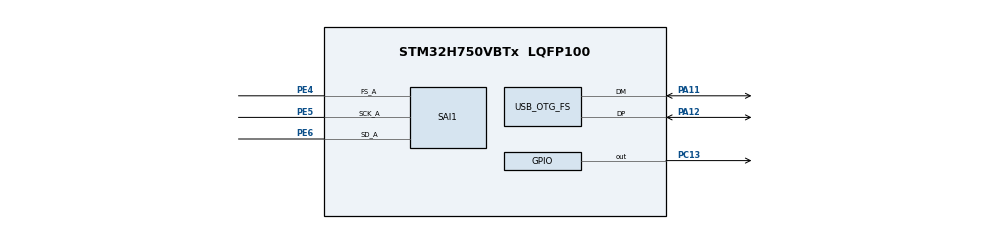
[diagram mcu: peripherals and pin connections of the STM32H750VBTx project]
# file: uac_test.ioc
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CORTEX_M7.default_mode_Activation=1
Dma.Request0=SAI1_A
Dma.SAI1_A.0.Direction=DMA_MEMORY_TO_PERIPH
Dma.SAI1_A.0.EventEnable=DISABLE
Dma.SAI1_A.0.FIFOMode=DMA_FIFOMODE_DISABLE
Dma.SAI1_A.0.Instance=DMA1_Stream0
Dma.SAI1_A.0.MemDataAlignment=DMA_MDATAALIGN_WORD
Dma.SAI1_A.0.MemInc=DMA_MINC_ENABLE
Dma.SAI1_A.0.Mode=DMA_CIRCULAR
Dma.SAI1_A.0.PeriphDataAlignment=DMA_PDATAALIGN_WORD
Dma.SAI1_A.0.PeriphInc=DMA_PINC_DISABLE
Dma.SAI1_A.0.Polarity=HAL_DMAMUX_REQ_GEN_RISING
Dma.SAI1_A.0.Priority=DMA_PRIORITY_LOW
Dma.SAI1_A.0.RequestNumber=1
Dma.SAI1_A.0.SignalID=NONE
Dma.SAI1_A.0.SyncEnable=DISABLE
Dma.SAI1_A.0.SyncPolarity=HAL_DMAMUX_SYNC_NO_EVENT
Dma.SAI1_A.0.SyncRequestNumber=1
Dma.SAI1_A.0.SyncSignalID=NONE
Mcu.Family=STM32H7
Mcu.Name=STM32H750VBTx
Mcu.Package=LQFP100
NVIC.DMA1_Stream0_IRQn=true\:0\:0\:false\:false\:true\:false\:true\:true
NVIC.OTG_FS_IRQn=true\:0\:0\:false\:false\:true\:false\:true\:true
NVIC.PriorityGroup=NVIC_PRIORITYGROUP_4
PA11.Mode=Device_Only
PA11.Signal=USB_OTG_FS_DM
PA12.Mode=Device_Only
PA12.Signal=USB_OTG_FS_DP
PA13\ (JTMS/SWDIO).Mode=Serial_Wire
PA13\ (JTMS/SWDIO).Signal=DEBUG_JTMS-SWDIO
PA14\ (JTCK/SWCLK).Mode=Serial_Wire
PA14\ (JTCK/SWCLK).Signal=DEBUG_JTCK-SWCLK
PC13.Signal=GPIO_Output
PE4.Mode=SAI_A_Master
PE4.Signal=SAI1_FS_A
PE5.Mode=SAI_A_Master
PE5.Signal=SAI1_SCK_A
PE6.Mode=SAI_A_Master
PE6.Signal=SAI1_SD_A
PH0-OSC_IN\ (PH0).Mode=HSE-External-Oscillator
PH0-OSC_IN\ (PH0).Signal=RCC_OSC_IN
PH1-OSC_OUT\ (PH1).Mode=HSE-External-Oscillator
PH1-OSC_OUT\ (PH1).Signal=RCC_OSC_OUT
ProjectManager.HeapSize=0x4000
ProjectManager.StackSize=0x1000
ProjectManager.TargetToolchain=CMake
RCC.ADCFreq_Value=24576004.028320312
RCC.APB1Freq_Value=120000000
RCC.APB2Freq_Value=120000000
RCC.APB3Freq_Value=120000000
RCC.APB4Freq_Value=120000000
RCC.CortexFreq_Value=480000000
RCC.D1PPRE=RCC_APB3_DIV2
RCC.D2PPRE1=RCC_APB1_DIV2
RCC.D2PPRE2=RCC_APB2_DIV2
RCC.D3PPRE=RCC_APB4_DIV2
RCC.DIVM1=1
RCC.DIVM2=2
RCC.DIVN1=240
RCC.DIVN2=393
RCC.DIVP2=32
RCC.DIVQ1=15
RCC.HCLKFreq_Value=240000000
RCC.HPRE=RCC_HCLK_DIV2
RCC.PLL2FRACN=1770
RCC.PLL3FRACN=0
RCC.PLLFRACN=0
RCC.PLLSourceVirtual=RCC_PLLSOURCE_CSI
RCC.SAI1CLockSelection=RCC_SAI1CLKSOURCE_PLL2
RCC.SPI123CLockSelection=RCC_SPI123CLKSOURCE_PLL2
RCC.SYSCLKFreq_VALUE=480000000
RCC.SYSCLKSource=RCC_SYSCLKSOURCE_PLLCLK
RCC.USBCLockSelection=RCC_USBCLKSOURCE_HSI48
RCC.USBFreq_Value=48000000
SAI1.AudioFrequency-SAI_A_Master=SAI_AUDIO_FREQUENCY_48K
SAI1.BasicDataSize-SAI_A_Master=SAI_PROTOCOL_DATASIZE_32BIT
SAI1.ErrorAudioFreq-SAI_A_Master=100.0 %
SAI1.InitProtocol-SAI_A_Master=Enable
SAI1.Instance-SAI_A_Master=SAI$Index_Block_A
SAI1.MClockEnable=SAI_MASTERCLOCK_DISABLE
SAI1.MonoStereoMode-SAI_A_Master=SAI_STEREOMODE
SAI1.NoDivider-SAI_A_Master=SAI_MCK_OVERSAMPLING_DISABLE
SAI1.RealAudioFreq-SAI_A_Master=96.0 KHz
SAI1.VirtualMode-SAI_A_Master=VM_MASTER
SAI1.VirtualProtocol-SAI_A_BASIC=VM_BASIC_PROTOCOL
USB_DEVICE.CLASS_NAME_FS=AUDIO
USB_DEVICE.MANUFACTURER_STRING-AUDIO_FS=STM32_6676
USB_DEVICE.PID_AUDIO_FS=0x5730
USB_DEVICE.PRODUCT_STRING_AUDIO_FS=Audio Class
USB_DEVICE.USBD_AUDIO_FREQ-AUDIO_FS=48000
USB_DEVICE.VirtualMode-AUDIO_FS=Audio
USB_DEVICE.VirtualModeFS=Audio_FS
USB_OTG_FS.VirtualMode=Device_Only
VP_MEMORYMAP_VS_MEMORYMAP.Mode=CurAppReg
VP_SAI1_VP_$IpInstance_SAIA_SAI_BASIC.Mode=SAI_A_BASIC
VP_USB_DEVICE_VS_USB_DEVICE_AUDIO_FS.Mode=AUDIO_FS
board=custom

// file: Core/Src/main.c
/* USER CODE BEGIN Header */
/**
  ******************************************************************************
  * @file           : main.c
  * @brief          : Main program body
  ******************************************************************************
  * @attention
  *
  * Copyright (c) 2026 STMicroelectronics.
  * All rights reserved.
  *
  * This software is licensed under terms that can be found in the LICENSE file
  * in the root directory of this software component.
  * If no LICENSE file comes with this software, it is provided AS-IS.
  *
  ******************************************************************************
  */
/* USER CODE END Header */
#include "main.h"
#include "dma.h"
#include "sai.h"
#include "usb_device.h"
#include "gpio.h"

/* USER CODE BEGIN Includes */
#include "math.h"
/* USER CODE END Includes */

void SystemClock_Config(void);
static void MPU_Config(void);

/* USER CODE BEGIN 0 */
//#define buff_len 192*2
//#define pi 3.14159265358979

//int32_t sine_wave[192];
//int32_t i2s_buff[100];

/* USER CODE END 0 */

int main(void)
{

  /* MPU Configuration--------------------------------------------------------*/
  MPU_Config();

  /* MCU Configuration--------------------------------------------------------*/

  /* Reset of all peripherals, Initializes the Flash interface and the Systick. */
  HAL_Init();

  /* Configure the system clock */
  SystemClock_Config();

  /* Initialize all configured peripherals */
  MX_GPIO_Init();
  MX_DMA_Init();
  MX_USB_DEVICE_Init();
  MX_SAI1_Init();
  /* USER CODE BEGIN 2 */

//		for(uint32_t i=0;i<buff_len/2;i++)
//	{
//		sine_wave[i]=2000000000.0*sin(2.0*pi*i/(buff_len/2));
//	}
//	for(uint32_t i=0;i<buff_len/2;i++)
//	{
//		uint32_t index_r=2*i+1;
//		uint32_t index_l=2*i;
//		if(i<buff_len/4)
//			i2s_buff[index_l]=(i-buff_len/8)*3000000;
//		else
//			i2s_buff[index_l]=(-i+buff_len*3/8)*3000000;
//
//		i2s_buff[index_r]=sine_wave[i];//i2s_buff[index_l]=sine_wave[i];
////		i2s_buff[index_r]=((i2s_buff[index_r]&0x0000ffff)<<16)|((i2s_buff[index_r]&0xffff0000)>>16);
////		i2s_buff[index_l]=((i2s_buff[index_l]&0x0000ffff)<<16)|((i2s_buff[index_l]&0xffff0000)>>16);
//	}
	//HAL_SAI_Transmit_DMA(&hsai_BlockA1,(uint8_t *)i2s_buff,100);
  /* USER CODE END 2 */

  /* Infinite loop */
  /* USER CODE BEGIN WHILE */
  while (1)
  {
		HAL_Delay(500);

    /* USER CODE END WHILE */

  }
}

void SystemClock_Config(void)
{
  RCC_OscInitTypeDef RCC_OscInitStruct = {0};
  RCC_ClkInitTypeDef RCC_ClkInitStruct = {0};

  /** Supply configuration update enable
  */
  HAL_PWREx_ConfigSupply(PWR_LDO_SUPPLY);

  /** Configure the main internal regulator output voltage
  */
  __HAL_PWR_VOLTAGESCALING_CONFIG(PWR_REGULATOR_VOLTAGE_SCALE0);

  while(!__HAL_PWR_GET_FLAG(PWR_FLAG_VOSRDY)) {}

  /** Initializes the RCC Oscillators according to the specified parameters
  * in the RCC_OscInitTypeDef structure.
  */
  RCC_OscInitStruct.OscillatorType = RCC_OSCILLATORTYPE_HSI48|RCC_OSCILLATORTYPE_CSI;
  RCC_OscInitStruct.HSI48State = RCC_HSI48_ON;
  RCC_OscInitStruct.CSIState = RCC_CSI_ON;
  RCC_OscInitStruct.CSICalibrationValue = RCC_CSICALIBRATION_DEFAULT;
  RCC_OscInitStruct.PLL.PLLState = RCC_PLL_ON;
  RCC_OscInitStruct.PLL.PLLSource = RCC_PLLSOURCE_CSI;
  RCC_OscInitStruct.PLL.PLLM = 1;
  RCC_OscInitStruct.PLL.PLLN = 240;
  RCC_OscInitStruct.PLL.PLLP = 2;
  RCC_OscInitStruct.PLL.PLLQ = 15;
  RCC_OscInitStruct.PLL.PLLR = 2;
  RCC_OscInitStruct.PLL.PLLRGE = RCC_PLL1VCIRANGE_2;
  RCC_OscInitStruct.PLL.PLLVCOSEL = RCC_PLL1VCOWIDE;
  RCC_OscInitStruct.PLL.PLLFRACN = 0;
  if (HAL_RCC_OscConfig(&RCC_OscInitStruct) != HAL_OK)
  {
    Error_Handler();
  }

  /** Initializes the CPU, AHB and APB buses clocks
  */
  RCC_ClkInitStruct.ClockType = RCC_CLOCKTYPE_HCLK|RCC_CLOCKTYPE_SYSCLK
                              |RCC_CLOCKTYPE_PCLK1|RCC_CLOCKTYPE_PCLK2
                              |RCC_CLOCKTYPE_D3PCLK1|RCC_CLOCKTYPE_D1PCLK1;
  RCC_ClkInitStruct.SYSCLKSource = RCC_SYSCLKSOURCE_PLLCLK;
  RCC_ClkInitStruct.SYSCLKDivider = RCC_SYSCLK_DIV1;
  RCC_ClkInitStruct.AHBCLKDivider = RCC_HCLK_DIV2;
  RCC_ClkInitStruct.APB3CLKDivider = RCC_APB3_DIV2;
  RCC_ClkInitStruct.APB1CLKDivider = RCC_APB1_DIV2;
  RCC_ClkInitStruct.APB2CLKDivider = RCC_APB2_DIV2;
  RCC_ClkInitStruct.APB4CLKDivider = RCC_APB4_DIV2;

  if (HAL_RCC_ClockConfig(&RCC_ClkInitStruct, FLASH_LATENCY_4) != HAL_OK)
  {
    Error_Handler();
  }
}

 /* MPU Configuration */

void MPU_Config(void)
{
  MPU_Region_InitTypeDef MPU_InitStruct = {0};

  /* Disables the MPU */
  HAL_MPU_Disable();

  /** Initializes and configures the Region and the memory to be protected
  */
  MPU_InitStruct.Enable = MPU_REGION_ENABLE;
  MPU_InitStruct.Number = MPU_REGION_NUMBER0;
  MPU_InitStruct.BaseAddress = 0x0;
  MPU_InitStruct.Size = MPU_REGION_SIZE_4GB;
  MPU_InitStruct.SubRegionDisable = 0x87;
  MPU_InitStruct.TypeExtField = MPU_TEX_LEVEL0;
  MPU_InitStruct.AccessPermission = MPU_REGION_NO_ACCESS;
  MPU_InitStruct.DisableExec = MPU_INSTRUCTION_ACCESS_DISABLE;
  MPU_InitStruct.IsShareable = MPU_ACCESS_SHAREABLE;
  MPU_InitStruct.IsCacheable = MPU_ACCESS_NOT_CACHEABLE;
  MPU_InitStruct.IsBufferable = MPU_ACCESS_NOT_BUFFERABLE;

  HAL_MPU_ConfigRegion(&MPU_InitStruct);
  /* Enables the MPU */
  HAL_MPU_Enable(MPU_PRIVILEGED_DEFAULT);

}

void Error_Handler(void)
{
  __disable_irq();
  while (1)
  {
  }
}
